# ATmega32 device description
Architecture: AVR8; Family: megaAVR
Registers are 8-bit, access not given, no defined reset value unless marked. A register's access mark holds for its fields unless they carry their own. Offsets are from the block's base; [hi:lo] are bit positions; 'fields as' and 'values as' point back to an identical list.

## LOCKBIT — Lockbits
Instances: LOCKBIT 0 in lockbits
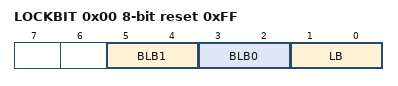
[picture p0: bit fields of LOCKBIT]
0x00 LOCKBIT reset 0xFF
  [5:4] BLB1 — Boot Loader Protection Mode
    0=LPM_SPM_DISABLE (LPM and SPM prohibited in Boot Section); 1=LPM_DISABLE (LPM prohibited in Boot Section); 2=SPM_DISABLE (SPM prohibited in Boot Section); 3=NO_LOCK (No lock on SPM and LPM in Boot Section)
  [3:2] BLB0 — Boot Loader Protection Mode
    0=LPM_SPM_DISABLE (LPM and SPM prohibited in Application Section); 1=LPM_DISABLE (LPM prohibited in Application Section); 2=SPM_DISABLE (SPM prohibited in Application Section); 3=NO_LOCK (No lock on SPM and LPM in Application Section)
  [1:0] LB — Memory Lock
    0=PROG_VER_DISABLED (Further programming and verification disabled); 2=PROG_DISABLED (Further programming disabled); 3=NO_LOCK (No memory lock features enabled)

## JTAG — JTAG Interface
Instances: JTAG 0x00
0x51 OCDR — On-Chip Debug Related Register in I/O Memory
  [7:0] OCDR — On-Chip Debug Register Bits
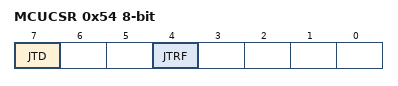
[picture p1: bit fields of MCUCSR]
0x54 MCUCSR — MCU Control And Status Register
  [7] JTD — JTAG Interface Disable
  [4] JTRF — JTAG Reset Flag

## EEPROM
Instances: EEPROM 0x00
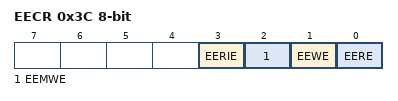
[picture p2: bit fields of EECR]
0x3C EECR — EEPROM Control Register
  [3] EERIE — EEPROM Ready Interrupt Enable
  [2] EEMWE — EEPROM Master Write Enable
  [1] EEWE — EEPROM Write Enable
  [0] EERE — EEPROM Read Enable
0x3D EEDR — EEPROM Data Register
0x3E EEAR 16-bit bits used 9:0 — EEPROM Read/Write Access Bytes

## WDT — Watchdog Timer
Instances: WDT 0x00
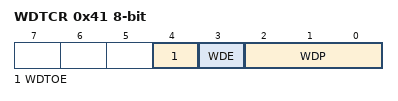
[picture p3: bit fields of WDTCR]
0x41 WDTCR — Watchdog Timer Control Register
  [4] WDTOE — RW
  [3] WDE — Watch Dog Enable
  [2:0] WDP — Watch Dog Timer Prescaler bits
    0=Oscillator Cycles 16K; 1=Oscillator Cycles 32K; 2=Oscillator Cycles 64K; 3=Oscillator Cycles 128K; 4=Oscillator Cycles 256K; 5=Oscillator Cycles 512K; 6=Oscillator Cycles 1024K; 7=Oscillator Cycles 2048K

## EXINT — External Interrupts
Instances: EXINT 0x00
0x54 MCUCSR — MCU Control And Status Register
  [6] ISC2 — Interrupt Sense Control 2
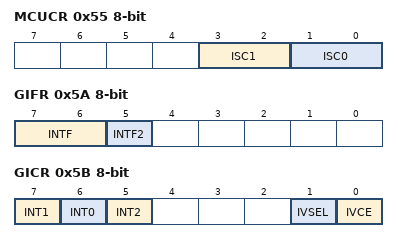
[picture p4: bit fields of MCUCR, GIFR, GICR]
0x55 MCUCR — General Interrupt Control Register
  [3:2] ISC1 — Interrupt Sense Control 1 Bits
    0=Low Level of INTX; 1=Any Logical Change of INTX; 2=Falling Edge of INTX; 3=Rising Edge of INTX
  [1:0] ISC0 — Interrupt Sense Control 0 Bits
    values as ISC1
0x5A GIFR — General Interrupt Flag Register
  [7:6] INTF — External Interrupt Flags
  [5] INTF2 — External Interrupt Flag 2
0x5B GICR — General Interrupt Control Register
  [7] INT1 — External Interrupt Request 1 Enable
  [6] INT0 — External Interrupt Request 0 Enable
  [5] INT2 — External Interrupt Request 2 Enable
  [1] IVSEL — Interrupt Vector Select
  [0] IVCE — Interrupt Vector Change Enable

## TC0 (TC8 module) — Timer/Counter, 8-bit
Instances: TC0 0x00
0x52 TCNT0 — Timer/Counter Register
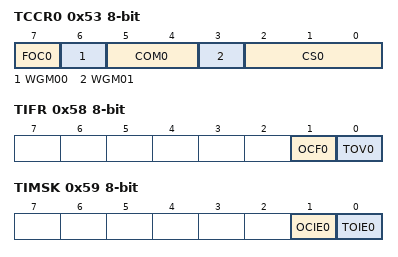
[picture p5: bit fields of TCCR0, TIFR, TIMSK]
0x53 TCCR0 — Timer/Counter Control Register
  [7] FOC0 — Force Output Compare
  [6] WGM00 — Waveform Generation Mode
    0=Normal; 2=PWM, Phase Correct; 1=CTC; 3=Fast PWM
  [5:4] COM0 — Compare Match Output Modes
  [3] WGM01 — Waveform Generation Mode 1
  [2:0] CS0 — Clock Selects
    0=No Clock Source (Stopped); 1=Running, No Prescaling; 2=Running, CLK/8; 3=Running, CLK/64; 4=Running, CLK/256; 5=Running, CLK/1024; 6=Running, ExtClk Tx Falling Edge; 7=Running, ExtClk Tx Rising Edge
0x58 TIFR — Timer/Counter Interrupt Flag register
  [1] OCF0 — Output Compare Flag 0
  [0] TOV0 — Timer/Counter0 Overflow Flag
0x59 TIMSK — Timer/Counter Interrupt Mask Register
  [1] OCIE0 — Timer/Counter0 Output Compare Match Interrupt register
  [0] TOIE0 — Timer/Counter0 Overflow Interrupt Enable
0x5C OCR0 — Output Compare Register

## TC2 (TC8_ASYNC module) — Timer/Counter, 8-bit Async
Instances: TC2 0x00
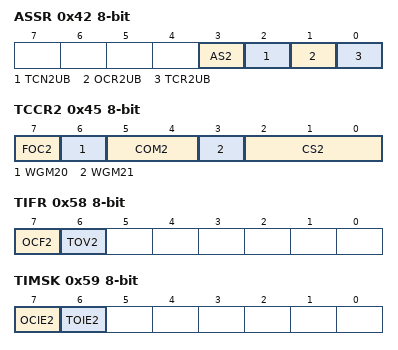
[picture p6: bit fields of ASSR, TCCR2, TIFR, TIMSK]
0x42 ASSR — Asynchronous Status Register
  [3] AS2 — Asynchronous Timer/counter2
  [2] TCN2UB — Timer/Counter2 Update Busy
  [1] OCR2UB — Output Compare Register2 Update Busy
  [0] TCR2UB — Timer/counter Control Register2 Update Busy
0x43 OCR2 — Timer/Counter2 Output Compare Register
0x44 TCNT2 — Timer/Counter2
0x45 TCCR2 — Timer/Counter2 Control Register
  [7] FOC2 — Force Output Compare
  [6] WGM20 — Pulse Width Modulator Enable
  [5:4] COM2 — Compare Output Mode bits
  [3] WGM21 — Clear Timer/Counter2 on Compare Match
  [2:0] CS2 — Clock Select bits
    0=No Clock Source (Stopped); 1=Running, No Prescaling; 2=Running, CLK/8; 3=Running, CLK/32; 4=Running, CLK/64; 5=Running, CLK/128; 6=Running, CLK/256; 7=Running, CLK/1024
0x58 TIFR — Timer/Counter Interrupt Flag Register
  [7] OCF2 — Output Compare Flag 2
  [6] TOV2 — Timer/Counter2 Overflow Flag
0x59 TIMSK — Timer/Counter Interrupt Mask register
  [7] OCIE2 — Timer/Counter2 Output Compare Match Interrupt Enable
  [6] TOIE2 — Timer/Counter2 Overflow Interrupt Enable
